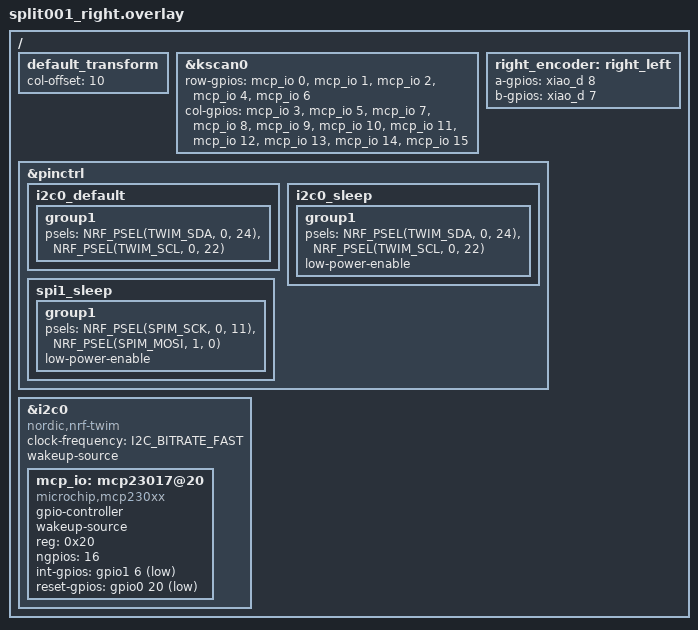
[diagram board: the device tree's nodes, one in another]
#include "split001.dtsi" //Shared between halves

/ {


default_transform {
    col-offset = <10>;
};

&kscan0 {
        row-gpios
            =   <&mcp_io 0 (GPIO_ACTIVE_HIGH | GPIO_PULL_DOWN)>,
                <&mcp_io 1 (GPIO_ACTIVE_HIGH | GPIO_PULL_DOWN)>,
                <&mcp_io 2 (GPIO_ACTIVE_HIGH | GPIO_PULL_DOWN)>,
                <&mcp_io 4 (GPIO_ACTIVE_HIGH | GPIO_PULL_DOWN)>,
                <&mcp_io 6 (GPIO_ACTIVE_HIGH | GPIO_PULL_DOWN)>;

        col-gpios
            =   <&mcp_io 3 (GPIO_ACTIVE_HIGH | GPIO_PULL_DOWN)>,
                <&mcp_io 5 (GPIO_ACTIVE_HIGH | GPIO_PULL_DOWN)>,
                <&mcp_io 7 (GPIO_ACTIVE_HIGH | GPIO_PULL_DOWN)>,
                <&mcp_io 8 (GPIO_ACTIVE_HIGH | GPIO_PULL_DOWN)>,
                <&mcp_io 9 (GPIO_ACTIVE_HIGH | GPIO_PULL_DOWN)>,
                <&mcp_io 10 (GPIO_ACTIVE_HIGH | GPIO_PULL_DOWN)>,
                <&mcp_io 11 (GPIO_ACTIVE_HIGH | GPIO_PULL_DOWN)>,
                <&mcp_io 12 (GPIO_ACTIVE_HIGH | GPIO_PULL_DOWN)>,
                <&mcp_io 13 (GPIO_ACTIVE_HIGH | GPIO_PULL_DOWN)>,
                <&mcp_io 14 (GPIO_ACTIVE_HIGH | GPIO_PULL_DOWN)>,
                <&mcp_io 15 (GPIO_ACTIVE_HIGH | GPIO_PULL_DOWN)>;
};

right_encoder: right_left {
        status = "okay";
        a-gpios = <&xiao_d 8 (GPIO_ACTIVE_HIGH | GPIO_PULL_UP)>;
        b-gpios = <&xiao_d 7 (GPIO_ACTIVE_HIGH | GPIO_PULL_UP)>;
    };


&pinctrl {

    // I2C for MCP23017
    i2c0_default: i2c0_default {
        group1 {
            psels = <NRF_PSEL(TWIM_SDA, 0, 24)>,
                    <NRF_PSEL(TWIM_SCL, 0, 22)>;
        };
    };
    i2c0_sleep: i2c0_sleep {
        group1 {
            psels = <NRF_PSEL(TWIM_SDA, 0, 24)>,
                    <NRF_PSEL(TWIM_SCL, 0, 22)>;
            low-power-enable;
        };
    };

    
    spi1_sleep: spi1_sleep {
        group1 {
            psels = <NRF_PSEL(SPIM_SCK, 0, 11)>,
                    <NRF_PSEL(SPIM_MOSI, 1, 0)>;
            low-power-enable;
        };
    };
};

&i2c0 {
    compatible = "nordic,nrf-twim";
    status = "okay";
    clock-frequency = <I2C_BITRATE_FAST>;
    wakeup-source;

    mcp_io: mcp23017@20 {
        compatible = "microchip,mcp230xx";
        status = "okay";
        gpio-controller;
        wakeup-source;
        reg = <0x20>;
        #gpio-cells = <2>;
        ngpios = <16>;
        int-gpios = <&gpio1 6 (GPIO_PULL_UP | GPIO_ACTIVE_LOW)>;
        reset-gpios = <&gpio0 20 (GPIO_PULL_UP | GPIO_ACTIVE_LOW)>;
    };
};
}
